# PMM__Power_Management_System_5 register map
Vendor: Texas Instruments
Peripheral module from a debugger description file (folder msp430).
Registers are 8-bit, read-write, reset 0x0 unless marked. A register's access mark holds for its fields unless they carry their own. Offsets are as the file gives them; lines under a group give offsets from that group; [hi:lo] are bit positions; {n}, {i} and the like mark numbered series; 'fields as' and 'values as' point back to an identical list; <NAME> marks a mode.

## PMM_Power_Management_System
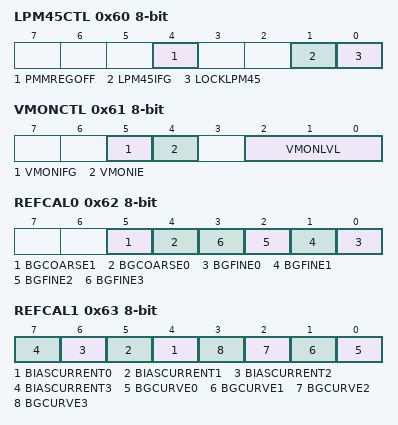
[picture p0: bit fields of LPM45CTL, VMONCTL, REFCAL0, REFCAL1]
0x60 LPM45CTL — PMM Power Mode 4.5 Control Register
  [4] PMMREGOFF — PMM Turn Regulator off
  [1] LPM45IFG — LPM4.5 interrupt flag
  [0] LOCKLPM45 — Lock I/O pin configuration upon entry/exit to/from LPM4.5
0x61 VMONCTL — PMM Voltage Monitor Control Register
  [5] VMONIFG — Voltage monitor interrupt flag
  [4] VMONIE — Voltage monitor interrupt enable
  [2:0] VMONLVL — Voltage monitor level selection Bit 0
    {v}=Voltage monitor level selection: {v} (v=0..7)
0x62 REFCAL0 — PMM Reference Calibration Register 0
  [5] BGCOARSE1 — Bandgap voltage coarse calibration Bit 1
  [4] BGCOARSE0 — Bandgap voltage coarse calibration Bit 0
  [n] BGFINE{n} (n=0..3) — Bandgap voltage fine calibration Bit {n}
0x63 REFCAL1 — PMM Reference Calibration Register 1
  [n+4] BIASCURRENT{n} (n=0..3) — Bandgap bias current calibration Bit {n}
  [n] BGCURVE{n} (n=0..3) — Curvature compensation Bit {n}
